# PIC16F1786 register map
Vendor: Microchip
Architecture 16Exxx. Special function registers and configuration words.
Registers are 8-bit, read-write, reset 0x0 unless marked. A register's access mark holds for its fields unless they carry their own. Addresses are absolute, and some are shared; only a register's first bit layout is shown; lines under a group give offsets from that group; [hi:lo] are bit positions; {n}, {i} and the like mark numbered series; 'fields as' and 'values as' point back to an identical list; <NAME> marks a mode.

## Further device data
pins=1: RE3/MCLR/Vpp; 2: RA0/AN0/C1IN0-/C2IN0-/C3IN0-/C4IN0-; 3: RA1/AN1/C1IN1-/C2IN1-/C3IN1-/C4IN1-/OPA1OUT; 4: RA2/AN2/C1IN0+/C2IN0+/C3IN0+/C4IN0+/DAC1OUT1/Vref-/DAC1Vref-; 5: RA3/AN3/Vref+/C1IN1+/DAC1Vref+; 6: RA4/C1OUT/OPA1IN+/T0CKI; 7: RA5/AN4/C2OUT/OPA1IN-/SS; 8: Vss; 9: RA7/PSMC1CLK/PSMC2CLK/PSMC3CLK/OSC1/CLKIN; 10: RA6/C2OUT/OSC2/CLKOUT/VCAP; 11: RC0/SOSCO/T1CKI/PSMC1A; 12: RC1/SOSCI/CCP2/PSMC1B; 13: RC2/CCP1/PSMC3B/PSMC1C; 14: RC3/SCK/SCL/PSMC1D; 15: RC4/SDI/SDA/PSMC1E; 16: RC5/SDO/PSMC3A/PSMC1F; 17: RC6/CCP3/TX/CK/PSMC2A; 18: RC7/C4OUT/RX/DT/PSMC2B; 19: Vss; 20: Vdd; 21: RB0/AN12/C2IN1+/PSMC1IN/PSMC2IN/PSMC3IN/CCP1/INT; 22: RB1/AN10/C1IN3-/C2IN3-/C3IN3-/C4IN3-/OPA2OUT; 23: RB2/AN8/OPA2IN-/CLKR; 24: RB3/AN9/C1IN2-/C2IN2-/C3IN2-/OPA2IN+/CCP2; 25: RB4/AN11/C3IN1+; 26: RB5/AN13/C4IN2-/T1G/CCP3/C3OUT/SDO; 27: RB6/TX/CK/SDI/SDA/C4IN1+/ICSPCLK/ICDCLK; 28: RB7/RX/DT/SCK/SCL/DAC1OUT2/ICSPDAT/ICDDAT

## cmp_rr
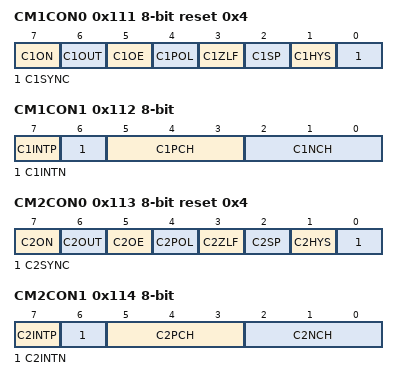
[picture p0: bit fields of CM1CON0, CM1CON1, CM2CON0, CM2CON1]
0x111 CM1CON0 reset 0x4
  [7] C1ON, [6] C1OUT ro, [5] C1OE, [4] C1POL, [3] C1ZLF, [2] C1SP, [1] C1HYS, [0] C1SYNC
0x112 CM1CON1
  [7] C1INTP, [6] C1INTN, [5:3] C1PCH, [2:0] C1NCH
0x113 CM2CON0 reset 0x4
  [7] C2ON, [6] C2OUT ro, [5] C2OE, [4] C2POL, [3] C2ZLF, [2] C2SP, [1] C2HYS, [0] C2SYNC
0x114 CM2CON1
  [7] C2INTP, [6] C2INTN, [5:3] C2PCH, [2:0] C2NCH
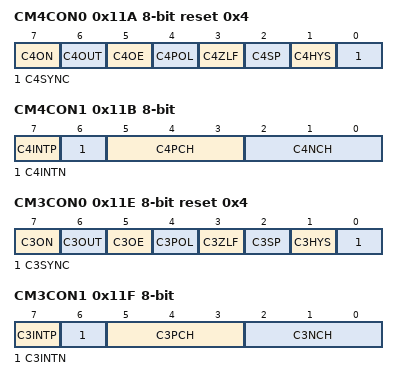
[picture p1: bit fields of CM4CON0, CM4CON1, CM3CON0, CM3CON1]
0x11A CM4CON0 reset 0x4
  [7] C4ON, [6] C4OUT ro, [5] C4OE, [4] C4POL, [3] C4ZLF, [2] C4SP, [1] C4HYS, [0] C4SYNC
0x11B CM4CON1
  [7] C4INTP, [6] C4INTN, [5:3] C4PCH, [2:0] C4NCH
0x11E CM3CON0 reset 0x4
  [7] C3ON, [6] C3OUT ro, [5] C3OE, [4] C3POL, [3] C3ZLF, [2] C3SP, [1] C3HYS, [0] C3SYNC
0x11F CM3CON1
  [7] C3INTP, [6] C3INTN, [5:3] C3PCH, [2:0] C3NCH

## mssp
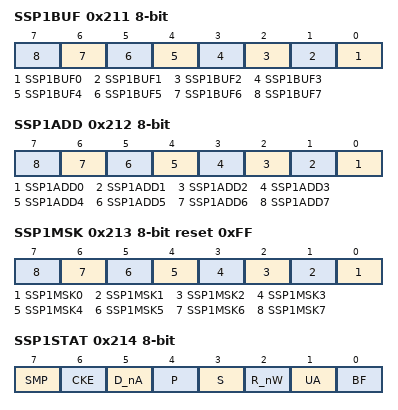
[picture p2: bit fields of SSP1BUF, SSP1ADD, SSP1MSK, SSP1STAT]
0x211 SSP1BUF reset not defined — (power-on value xxxxxxxx)
  [n] SSP1BUF{n} (n=0..7)
0x212 SSP1ADD
  [n] SSP1ADD{n} (n=0..7)
0x213 SSP1MSK reset 0xFF
  [n] SSP1MSK{n} (n=0..7)
0x214 SSP1STAT
  [7] SMP, [6] CKE, [5] D_nA ro, [4] P ro, [3] S ro, [2] R_nW ro, [1] UA ro, [0] BF ro
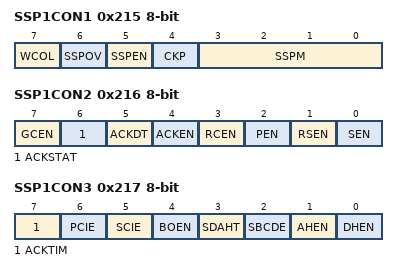
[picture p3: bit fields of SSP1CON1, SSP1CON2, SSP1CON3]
0x215 SSP1CON1
  [7] WCOL ro, [6] SSPOV ro, [5] SSPEN, [4] CKP, [3:0] SSPM
0x216 SSP1CON2
  [7] GCEN, [6] ACKSTAT ro, [5] ACKDT, [4] ACKEN, [3] RCEN, [2] PEN, [1] RSEN, [0] SEN
0x217 SSP1CON3
  [7] ACKTIM ro, [6] PCIE, [5] SCIE, [4] BOEN, [3] SDAHT, [2] SBCDE, [1] AHEN, [0] DHEN

## DOS_CCPx
0x291 CCPR1L reset not defined — (power-on value xxxxxxxx)
0x292 CCPR1H reset not defined — (power-on value xxxxxxxx)
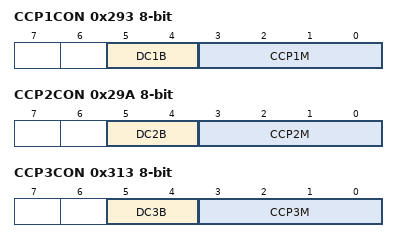
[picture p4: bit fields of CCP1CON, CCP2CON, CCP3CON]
0x293 CCP1CON
  [5:4] DC1B, [3:0] CCP1M
0x298 CCPR2L reset not defined — (power-on value xxxxxxxx)
0x299 CCPR2H reset not defined — (power-on value xxxxxxxx)
0x29A CCP2CON
  [5:4] DC2B, [3:0] CCP2M
0x311 CCPR3L reset not defined — (power-on value xxxxxxxx)
0x312 CCPR3H reset not defined — (power-on value xxxxxxxx)
0x313 CCP3CON
  [5:4] DC3B, [3:0] CCP3M

## DOS_OPAMP_amp_opamp_hvpump
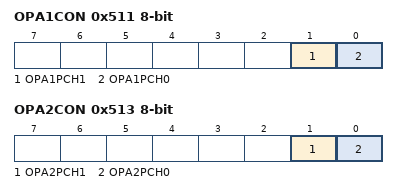
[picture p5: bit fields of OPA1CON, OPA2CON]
0x511 OPA1CON
  [1] OPA1PCH1, [0] OPA1PCH0
0x513 OPA2CON
  [1] OPA2PCH1, [0] OPA2PCH0
